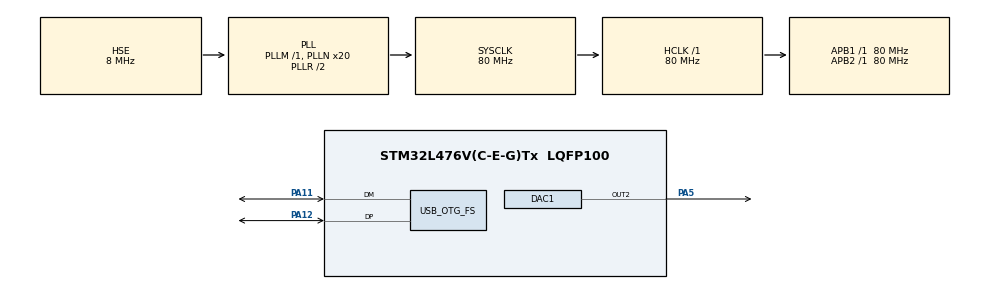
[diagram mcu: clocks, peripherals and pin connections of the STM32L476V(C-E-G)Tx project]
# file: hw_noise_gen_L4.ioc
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DAC1.DAC_Channel-DAC_OUT2=DAC_CHANNEL_2
Mcu.Family=STM32L4
Mcu.Name=STM32L476V(C-E-G)Tx
Mcu.Package=LQFP100
NVIC.OTG_FS_IRQn=true\:0\:0\:false\:false\:true\:false\:true
NVIC.PriorityGroup=NVIC_PRIORITYGROUP_4
NVIC.TIM4_IRQn=true\:1\:0\:true\:false\:true\:true\:true
PA11.Mode=Device_Only
PA11.Signal=USB_OTG_FS_DM
PA12.Mode=Device_Only
PA12.Signal=USB_OTG_FS_DP
PA13\ (JTMS-SWDIO).Mode=Serial_Wire
PA13\ (JTMS-SWDIO).Signal=SYS_JTMS-SWDIO
PA14\ (JTCK-SWCLK).Mode=Serial_Wire
PA14\ (JTCK-SWCLK).Signal=SYS_JTCK-SWCLK
PA5.Signal=COMP_DAC12_group
PH0-OSC_IN\ (PH0).Mode=HSE-External-Clock-Source
PH0-OSC_IN\ (PH0).Signal=RCC_OSC_IN
ProjectManager.HeapSize=0x800
ProjectManager.StackSize=0x400
ProjectManager.TargetToolchain=Makefile
RCC.ADCFreq_Value=48000000
RCC.AHBFreq_Value=80000000
RCC.APB1Freq_Value=80000000
RCC.APB1TimFreq_Value=80000000
RCC.APB2Freq_Value=80000000
RCC.APB2TimFreq_Value=80000000
RCC.CortexFreq_Value=80000000
RCC.HCLKFreq_Value=80000000
RCC.HSE_VALUE=8000000
RCC.HSI_VALUE=16000000
RCC.LSE_VALUE=32768
RCC.MSI_VALUE=4000000
RCC.PLLN=20
RCC.PLLSAI1N=12
RCC.PLLSourceVirtual=RCC_PLLSOURCE_HSE
RCC.SYSCLKFreq_VALUE=80000000
RCC.SYSCLKSource=RCC_SYSCLKSOURCE_PLLCLK
RCC.USBFreq_Value=48000000
RCC.VCOOutputFreq_Value=160000000
SH.COMP_DAC12_group.0=DAC1_OUT2,DAC_OUT2
TIM4.Period=1000
TIM4.TIM_MasterOutputTrigger=TIM_TRGO_UPDATE
USB_DEVICE.CLASS_NAME_FS=CDC
USB_DEVICE.VirtualMode=Cdc
USB_DEVICE.VirtualModeFS=Cdc_FS
USB_OTG_FS.VirtualMode=Device_Only
VP_RNG_VS_RNG.Mode=RNG_Activate
VP_TIM4_VS_ClockSourceINT.Mode=Internal
VP_USB_DEVICE_VS_USB_DEVICE_CDC_FS.Mode=CDC_FS
board=custom

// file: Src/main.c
/* USER CODE BEGIN Header */
/**
  ******************************************************************************
  * @file           : main.c
  * @brief          : Main program body
  ******************************************************************************
  * @attention
  *
  * <h2><center>&copy; Copyright (c) 2020 STMicroelectronics.
  * All rights reserved.</center></h2>
  *
  * This software component is licensed by ST under Ultimate Liberty license
  * SLA0044, the "License"; You may not use this file except in compliance with
  * the License. You may obtain a copy of the License at:
  *                             www.st.com/SLA0044
  *
  ******************************************************************************
  */
/* USER CODE END Header */

#include "main.h"
#include "usb_device.h"

/* USER CODE BEGIN Includes */
#include "arm_math.h"
#include "commands.h"
/* USER CODE END Includes */

DAC_HandleTypeDef hdac1;

RNG_HandleTypeDef hrng;

TIM_HandleTypeDef htim4;

/* USER CODE BEGIN PV */
#define BLOCK_SIZE            1
#define NUM_TAPS              129

float32_t in_buffer[BLOCK_SIZE];
float32_t out_buffer[BLOCK_SIZE];
float32_t  *inputF32 = &in_buffer[0],
           *outputF32 = &out_buffer[0];

arm_fir_instance_f32 S[3], test_str;

static float32_t firStateF32_fb[BLOCK_SIZE + NUM_TAPS - 1];
static float32_t firStateF32_hb[BLOCK_SIZE + NUM_TAPS - 1];
static float32_t firStateF32_oob[BLOCK_SIZE + NUM_TAPS - 1];
static float32_t state_test[BLOCK_SIZE + NUM_TAPS - 1];

extern float32_t firCoeffs_fb[NUM_TAPS];
extern float32_t firCoeffs_hb[NUM_TAPS];
extern float32_t firCoeffs_oob[NUM_TAPS];
extern float32_t test[NUM_TAPS];

uint32_t blockSize = BLOCK_SIZE;

float32_t V_max, V_min, V_avg;
/* USER CODE END PV */

void SystemClock_Config(void);
static void MX_GPIO_Init(void);
static void MX_DAC1_Init(void);
static void MX_TIM4_Init(void);
static void MX_RNG_Init(void);

int main(void)
{

  /* MCU Configuration--------------------------------------------------------*/

  /* Reset of all peripherals, Initializes the Flash interface and the Systick. */
  HAL_Init();

  /* Configure the system clock */
  SystemClock_Config();

  /* Initialize all configured peripherals */
  MX_GPIO_Init();
  MX_DAC1_Init();
  MX_TIM4_Init();
  MX_USB_DEVICE_Init();
  MX_RNG_Init();
  /* USER CODE BEGIN 2 */

  arm_fir_init_f32(&S[0], NUM_TAPS, (float32_t *)&firCoeffs_fb[0], (float32_t *)&firStateF32_fb[0], blockSize);
  arm_fir_init_f32(&S[1], NUM_TAPS, (float32_t *)&firCoeffs_hb[0], (float32_t *)&firStateF32_hb[0], blockSize);
  arm_fir_init_f32(&S[2], NUM_TAPS, (float32_t *)&firCoeffs_oob[0], (float32_t *)&firStateF32_oob[0], blockSize);
  arm_fir_init_f32(&test_str, NUM_TAPS, (float32_t *)&test[0], (float32_t *)&state_test[0], blockSize);

  HAL_TIM_Base_Start_IT(&htim4);
  /* USER CODE END 2 */

  /* Infinite loop */
  while (1)
  {

  }
}

void SystemClock_Config(void)
{
  RCC_OscInitTypeDef RCC_OscInitStruct = {0};
  RCC_ClkInitTypeDef RCC_ClkInitStruct = {0};
  RCC_PeriphCLKInitTypeDef PeriphClkInit = {0};

  /** Initializes the CPU, AHB and APB busses clocks
  */
  RCC_OscInitStruct.OscillatorType = RCC_OSCILLATORTYPE_HSE;
  RCC_OscInitStruct.HSEState = RCC_HSE_BYPASS;
  RCC_OscInitStruct.PLL.PLLState = RCC_PLL_ON;
  RCC_OscInitStruct.PLL.PLLSource = RCC_PLLSOURCE_HSE;
  RCC_OscInitStruct.PLL.PLLM = 1;
  RCC_OscInitStruct.PLL.PLLN = 20;
  RCC_OscInitStruct.PLL.PLLP = RCC_PLLP_DIV7;
  RCC_OscInitStruct.PLL.PLLQ = RCC_PLLQ_DIV2;
  RCC_OscInitStruct.PLL.PLLR = RCC_PLLR_DIV2;
  if (HAL_RCC_OscConfig(&RCC_OscInitStruct) != HAL_OK)
  {
    Error_Handler();
  }
  /** Initializes the CPU, AHB and APB busses clocks
  */
  RCC_ClkInitStruct.ClockType = RCC_CLOCKTYPE_HCLK|RCC_CLOCKTYPE_SYSCLK
                              |RCC_CLOCKTYPE_PCLK1|RCC_CLOCKTYPE_PCLK2;
  RCC_ClkInitStruct.SYSCLKSource = RCC_SYSCLKSOURCE_PLLCLK;
  RCC_ClkInitStruct.AHBCLKDivider = RCC_SYSCLK_DIV1;
  RCC_ClkInitStruct.APB1CLKDivider = RCC_HCLK_DIV1;
  RCC_ClkInitStruct.APB2CLKDivider = RCC_HCLK_DIV1;

  if (HAL_RCC_ClockConfig(&RCC_ClkInitStruct, FLASH_LATENCY_4) != HAL_OK)
  {
    Error_Handler();
  }
  PeriphClkInit.PeriphClockSelection = RCC_PERIPHCLK_USB|RCC_PERIPHCLK_RNG;
  PeriphClkInit.UsbClockSelection = RCC_USBCLKSOURCE_PLLSAI1;
  PeriphClkInit.RngClockSelection = RCC_RNGCLKSOURCE_PLLSAI1;
  PeriphClkInit.PLLSAI1.PLLSAI1Source = RCC_PLLSOURCE_HSE;
  PeriphClkInit.PLLSAI1.PLLSAI1M = 1;
  PeriphClkInit.PLLSAI1.PLLSAI1N = 12;
  PeriphClkInit.PLLSAI1.PLLSAI1P = RCC_PLLP_DIV7;
  PeriphClkInit.PLLSAI1.PLLSAI1Q = RCC_PLLQ_DIV2;
  PeriphClkInit.PLLSAI1.PLLSAI1R = RCC_PLLR_DIV2;
  PeriphClkInit.PLLSAI1.PLLSAI1ClockOut = RCC_PLLSAI1_48M2CLK;
  if (HAL_RCCEx_PeriphCLKConfig(&PeriphClkInit) != HAL_OK)
  {
    Error_Handler();
  }
  /** Configure the main internal regulator output voltage
  */
  if (HAL_PWREx_ControlVoltageScaling(PWR_REGULATOR_VOLTAGE_SCALE1) != HAL_OK)
  {
    Error_Handler();
  }
}

static void MX_DAC1_Init(void)
{

  DAC_ChannelConfTypeDef sConfig = {0};

  /** DAC Initialization
  */
  hdac1.Instance = DAC1;
  if (HAL_DAC_Init(&hdac1) != HAL_OK)
  {
    Error_Handler();
  }
  /** DAC channel OUT2 config
  */
  sConfig.DAC_SampleAndHold = DAC_SAMPLEANDHOLD_DISABLE;
  sConfig.DAC_Trigger = DAC_TRIGGER_NONE;
  sConfig.DAC_OutputBuffer = DAC_OUTPUTBUFFER_ENABLE;
  sConfig.DAC_ConnectOnChipPeripheral = DAC_CHIPCONNECT_DISABLE;
  sConfig.DAC_UserTrimming = DAC_TRIMMING_FACTORY;
  if (HAL_DAC_ConfigChannel(&hdac1, &sConfig, DAC_CHANNEL_2) != HAL_OK)
  {
    Error_Handler();
  }

}

static void MX_RNG_Init(void)
{

  hrng.Instance = RNG;
  if (HAL_RNG_Init(&hrng) != HAL_OK)
  {
    Error_Handler();
  }

}

static void MX_TIM4_Init(void)
{

  TIM_ClockConfigTypeDef sClockSourceConfig = {0};
  TIM_MasterConfigTypeDef sMasterConfig = {0};

  htim4.Instance = TIM4;
  htim4.Init.Prescaler = 0;
  htim4.Init.CounterMode = TIM_COUNTERMODE_UP;
  htim4.Init.Period = F_APB1/F_SAMPLING - 1;
  htim4.Init.ClockDivision = TIM_CLOCKDIVISION_DIV1;
  htim4.Init.AutoReloadPreload = TIM_AUTORELOAD_PRELOAD_DISABLE;
  if (HAL_TIM_Base_Init(&htim4) != HAL_OK)
  {
    Error_Handler();
  }
  sClockSourceConfig.ClockSource = TIM_CLOCKSOURCE_INTERNAL;
  if (HAL_TIM_ConfigClockSource(&htim4, &sClockSourceConfig) != HAL_OK)
  {
    Error_Handler();
  }
  sMasterConfig.MasterOutputTrigger = TIM_TRGO_UPDATE;
  sMasterConfig.MasterSlaveMode = TIM_MASTERSLAVEMODE_DISABLE;
  if (HAL_TIMEx_MasterConfigSynchronization(&htim4, &sMasterConfig) != HAL_OK)
  {
    Error_Handler();
  }

}

static void MX_GPIO_Init(void)
{

  /* GPIO Ports Clock Enable */
  __HAL_RCC_GPIOH_CLK_ENABLE();
  __HAL_RCC_GPIOA_CLK_ENABLE();

}

/* USER CODE BEGIN 4 */

void HAL_TIM_PeriodElapsedCallback(TIM_HandleTypeDef *htim)
{
  uint32_t Noise_Value;
  while (HAL_RNG_GenerateRandomNumber(&hrng, &Noise_Value));
  in_buffer[0] = (Noise_Value & 0x00000FFF) /act_attenuation;
  //in_buffer[0] = (Noise_Value & 0x00000FFF) / 5;
  //add_sample((float32_t)Noise_Value);
  //arm_fir_f32(&S[0], inputF32, outputF32, blockSize);
  arm_fir_f32(&S[act_band], inputF32, outputF32, blockSize);
  if (num_norm_samp != 0){
    if (num_norm_samp == 1000) V_avg = 0;
    V_avg = V_avg + out_buffer[BLOCK_SIZE - 1] / 1000;
    num_norm_samp--;
  }
  else
  {
    out_buffer[BLOCK_SIZE - 1] = out_buffer[BLOCK_SIZE - 1] + 2048.0 - V_avg;
    HAL_DAC_SetValue(&hdac1,DAC_CHANNEL_2,DAC_ALIGN_12B_R, (uint32_t)out_buffer[BLOCK_SIZE - 1]);
  }
  //HAL_DAC_SetValue(&hdac1,DAC_CHANNEL_2,DAC_ALIGN_12B_R, ((uint32_t)out_buffer[BLOCK_SIZE - 1]));

}
/* USER CODE END 4 */

void Error_Handler(void)
{
}

/************************ (C) COPYRIGHT STMicroelectronics *****END OF FILE****/
